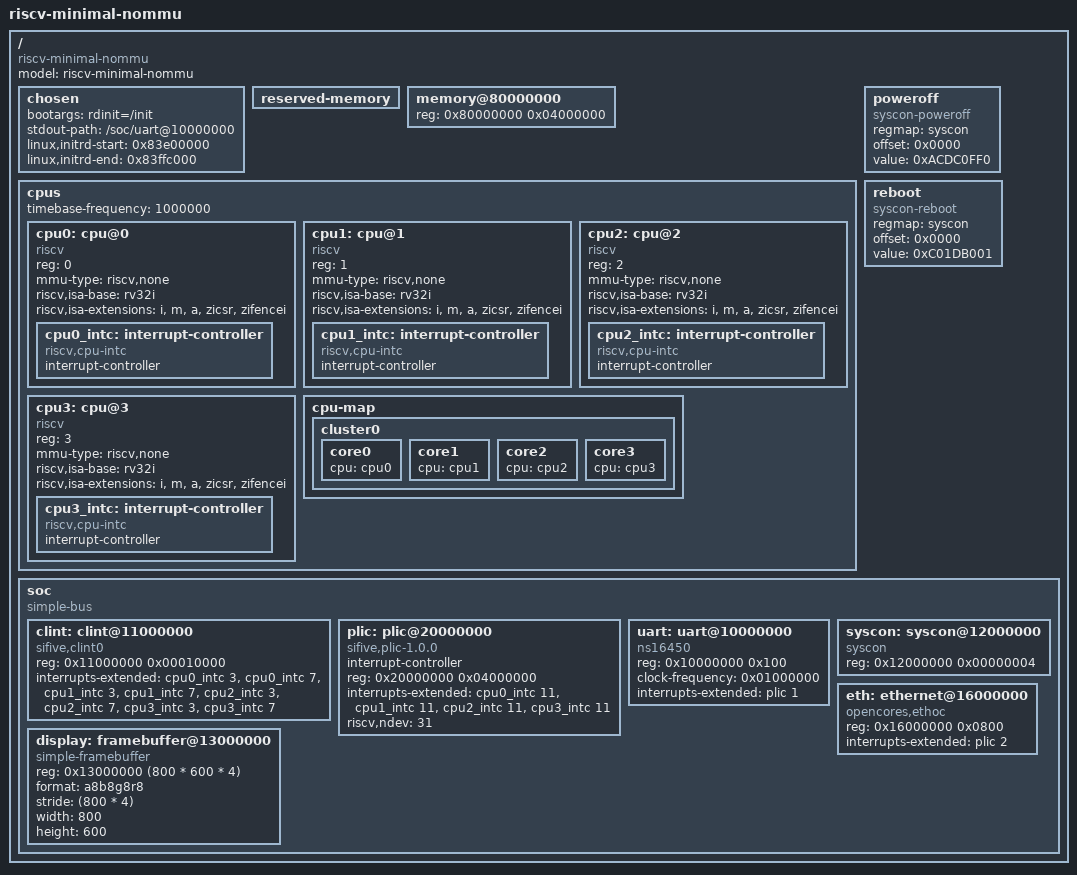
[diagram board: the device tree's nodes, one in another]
/dts-v1/;

/ {
	#address-cells = <1>;
	#size-cells = <1>;

	compatible = "riscv-minimal-nommu";
	model = "riscv-minimal-nommu";

	chosen {
		bootargs = "rdinit=/init"; /* earlycon=uart8250,mmio,0x10000000 */

		stdout-path = "/soc/uart@10000000";
		linux,initrd-start = <0x83e00000>;
		linux,initrd-end   = <0x83ffc000>;
	};

	reserved-memory {
		#address-cells = <1>;
		#size-cells = <1>;
		ranges;
	};

	memory@80000000 {
		device_type = "memory";
		reg = <0x80000000 0x04000000>;
	};

	cpus {
		#address-cells = <1>;
		#size-cells = <0>;
		timebase-frequency = <1000000>;

		cpu0: cpu@0 {
			device_type = "cpu";
			compatible = "riscv";
			reg = <0>;
			mmu-type = "riscv,none";
			riscv,isa-base = "rv32i";
			riscv,isa-extensions = "i", "m", "a", "zicsr", "zifencei";
			status = "ok";

			/* interrupts: 3 (software) 7 (timer) 11 (external) */
			cpu0_intc: interrupt-controller {
				#interrupt-cells = <1>;
				interrupt-controller;
				compatible = "riscv,cpu-intc";
			};
		};

		cpu1: cpu@1 {
			device_type = "cpu";
			compatible = "riscv";
			reg = <1>;
			mmu-type = "riscv,none";
			riscv,isa-base = "rv32i";
			riscv,isa-extensions = "i", "m", "a", "zicsr", "zifencei";
			status = "ok";

			/* interrupts: 3 (software) 7 (timer) 11 (external) */
			cpu1_intc: interrupt-controller {
				#interrupt-cells = <1>;
				interrupt-controller;
				compatible = "riscv,cpu-intc";
			};
		};

		cpu2: cpu@2 {
			device_type = "cpu";
			compatible = "riscv";
			reg = <2>;
			mmu-type = "riscv,none";
			riscv,isa-base = "rv32i";
			riscv,isa-extensions = "i", "m", "a", "zicsr", "zifencei";
			status = "ok";

			/* interrupts: 3 (software) 7 (timer) 11 (external) */
			cpu2_intc: interrupt-controller {
				#interrupt-cells = <1>;
				interrupt-controller;
				compatible = "riscv,cpu-intc";
			};
		};

		cpu3: cpu@3 {
			device_type = "cpu";
			compatible = "riscv";
			reg = <3>;
			mmu-type = "riscv,none";
			riscv,isa-base = "rv32i";
			riscv,isa-extensions = "i", "m", "a", "zicsr", "zifencei";
			status = "ok";

			/* interrupts: 3 (software) 7 (timer) 11 (external) */
			cpu3_intc: interrupt-controller {
				#interrupt-cells = <1>;
				interrupt-controller;
				compatible = "riscv,cpu-intc";
			};
		};

		cpu-map {
			cluster0 {
				core0 {
					cpu = <&cpu0>;
				};

				core1 {
					cpu = <&cpu1>;
				};

				core2 {
					cpu = <&cpu2>;
				};

				core3 {
					cpu = <&cpu3>;
				};
			};
		};
	};

	poweroff {
		compatible = "syscon-poweroff";
		regmap = <&syscon>;
		offset = <0x0000>;
		value  = <0xACDC0FF0>;
	};

	reboot {
		compatible = "syscon-reboot";
		regmap = <&syscon>;
		offset = <0x0000>;
		value  = <0xC01DB001>;
	};

	soc {
		#address-cells = <1>;
		#size-cells = <1>;
		compatible = "simple-bus";
		ranges;

		clint: clint@11000000 {
			compatible = "sifive,clint0", "riscv,clint0";
			reg = <0x11000000 0x00010000>;
			interrupts-extended = <&cpu0_intc 3 &cpu0_intc 7>,
			                      <&cpu1_intc 3 &cpu1_intc 7>,
			                      <&cpu2_intc 3 &cpu2_intc 7>,
			                      <&cpu3_intc 3 &cpu3_intc 7>;
			status = "ok";
		};

		plic: plic@20000000 {
			#interrupt-cells = <1>;
			interrupt-controller;
			compatible = "sifive,plic-1.0.0", "riscv,plic0";
			reg = <0x20000000 0x04000000>;
			interrupts-extended = <&cpu0_intc 11
			                       &cpu1_intc 11
			                       &cpu2_intc 11
			                       &cpu3_intc 11>;
			riscv,ndev = <31>;
			status = "ok";
		};

		uart: uart@10000000 {
			compatible = "ns16450";
			reg = <0x10000000 0x100>;
			clock-frequency = <0x01000000>;
			interrupts-extended = <&plic 1>;
			status = "ok";
		};

		syscon: syscon@12000000 {
			compatible = "syscon";
			reg = <0x12000000 0x00000004>;
			status = "ok";
		};

		eth: ethernet@16000000 {
			#address-cells = <1>;
			#size-cells = <0>;
			compatible = "opencores,ethoc";
			reg = <0x16000000 0x0800>;
			interrupts-extended = <&plic 2>;
			status = "ok";
		};

		display: framebuffer@13000000 {
			compatible = "simple-framebuffer";
			reg = <0x13000000 (800 * 600 * 4)>;
			format = "a8b8g8r8";
			stride = <(800 * 4)>;
			width  = <800>;
			height = <600>;
			status = "ok";
		};
	};
};
